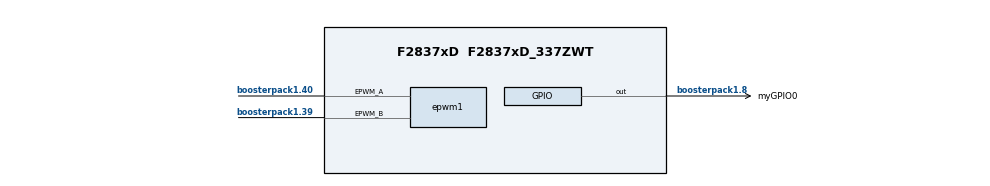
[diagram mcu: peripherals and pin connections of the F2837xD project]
/**
 * @cliArgs --board "/boards/LAUNCHXL_F28379D" --device "F2837xD" --part "F2837xD_337ZWT" --package "F2837xD_337ZWT" --context "CPU1" --product "C2000WARE@5.04.00.00"
 * @versions {"tool":"1.21.0+3721"}
 */

/**
 * Import the modules used in this configuration.
 */
const cputimer         = scripting.addModule("/driverlib/cputimer.js", {}, false);
const cputimer1        = cputimer.addInstance();
const dac              = scripting.addModule("/driverlib/dac.js", {}, false);
const dac1             = dac.addInstance();
const epwm             = scripting.addModule("/driverlib/epwm.js", {}, false);
const epwm1            = epwm.addInstance();
const gpio             = scripting.addModule("/driverlib/gpio.js", {}, false);
const gpio1            = gpio.addInstance();
const inputxbar_input  = scripting.addModule("/driverlib/inputxbar_input.js", {}, false);
const inputxbar_input1 = inputxbar_input.addInstance();

/**
 * Write custom configuration values to the imported modules.
 */
cputimer1.$name                    = "myCPUTIMER0";
cputimer1.startTimer               = true;
cputimer1.enableInterrupt          = true;
cputimer1.emulationMode            = "CPUTIMER_EMULATIONMODE_RUNFREE";
cputimer1.registerInterrupts       = true;
cputimer1.timerPeriod              = 999;
cputimer1.timerInt.enableInterrupt = true;

dac1.$name            = "DAC0";
dac1.enableOutput     = true;
dac1.dacBase          = "DACB_BASE";
dac1.referenceVoltage = "DAC_REF_ADC_VREFHI";

epwm1.$name                                                      = "EPWM0";
epwm1.epwmTimebase_hsClockDiv                                    = "EPWM_HSCLOCK_DIVIDER_1";
epwm1.epwmTimebase_counterMode                                   = "EPWM_COUNTER_MODE_UP_DOWN";
epwm1.epwmActionQualifier_EPWM_AQ_OUTPUT_A_shadowMode            = true;
epwm1.epwmActionQualifier_EPWM_AQ_OUTPUT_A_ON_TIMEBASE_UP_CMPA   = "EPWM_AQ_OUTPUT_HIGH";
epwm1.epwmActionQualifier_EPWM_AQ_OUTPUT_A_ON_TIMEBASE_DOWN_CMPA = "EPWM_AQ_OUTPUT_LOW";
epwm1.epwmCounterCompare_cmpB                                    = 100;
epwm1.epwmTimebase_period                                        = 5000;
epwm1.epwmCounterCompare_cmpA                                    = 3750;
epwm1.epwm.$assign                                               = "EPWM1";
epwm1.epwm.epwm_aPin.$assign                                     = "boosterpack1.40";
epwm1.epwm.epwm_bPin.$assign                                     = "boosterpack1.39";

gpio1.$name                     = "myGPIO0";
gpio1.useInterrupt              = true;
gpio1.gpioPin.$assign           = "boosterpack1.8";
gpio1.xint.intType              = "GPIO_INT_TYPE_BOTH_EDGES";
gpio1.xint.registerInterrupts   = true;
gpio1.xint.enableInt            = true;
gpio1.xint.xInt.enableInterrupt = true;

inputxbar_input1.$name         = "myINPUTXBARINPUT0";
gpio1.xint.inputxbar           = inputxbar_input1;
inputxbar_input1.inputxbarGpio = "GPIO22";
